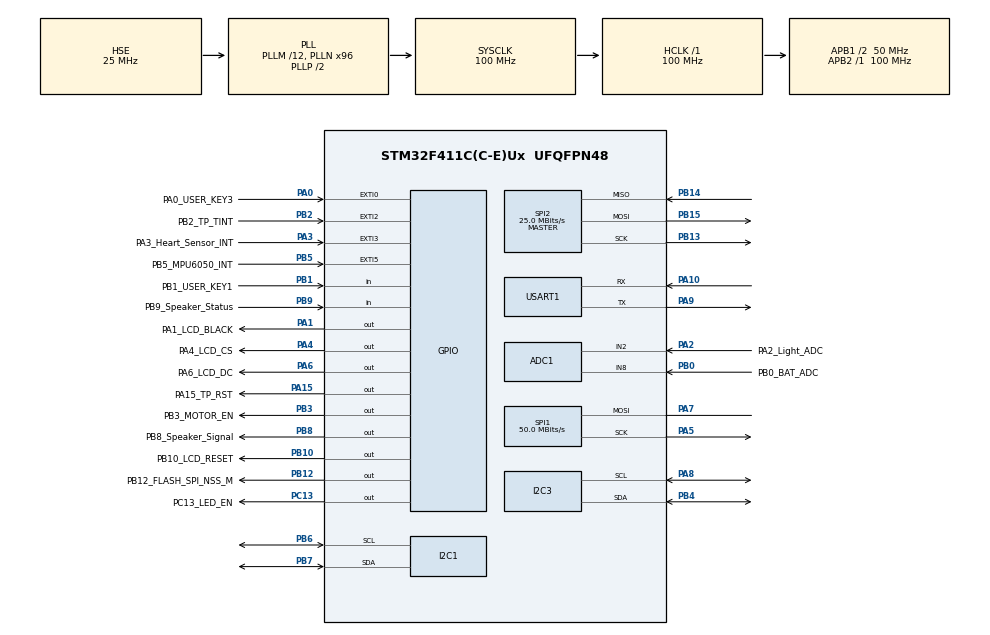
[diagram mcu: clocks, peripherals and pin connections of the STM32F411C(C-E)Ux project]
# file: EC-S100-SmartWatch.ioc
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ADC1.Channel-0\#ChannelRegularConversion=ADC_CHANNEL_8
ADC1.Channel-4\#ChannelRegularConversion=ADC_CHANNEL_VREFINT
ADC1.Channel-5\#ChannelRegularConversion=ADC_CHANNEL_8
ADC1.InjNumberOfConversion=0
ADC1.NbrOfConversion=3
ADC1.NbrOfConversionFlag=1
ADC1.Rank-0\#ChannelRegularConversion=1
ADC1.Rank-4\#ChannelRegularConversion=2
ADC1.Rank-5\#ChannelRegularConversion=3
ADC1.SamplingTime-0\#ChannelRegularConversion=ADC_SAMPLETIME_480CYCLES
ADC1.SamplingTime-4\#ChannelRegularConversion=ADC_SAMPLETIME_480CYCLES
ADC1.SamplingTime-5\#ChannelRegularConversion=ADC_SAMPLETIME_480CYCLES
ADC1.master=1
Dma.I2C1_RX.1.Direction=DMA_PERIPH_TO_MEMORY
Dma.I2C1_RX.1.FIFOMode=DMA_FIFOMODE_DISABLE
Dma.I2C1_RX.1.Instance=DMA1_Stream5
Dma.I2C1_RX.1.MemDataAlignment=DMA_MDATAALIGN_BYTE
Dma.I2C1_RX.1.MemInc=DMA_MINC_ENABLE
Dma.I2C1_RX.1.Mode=DMA_NORMAL
Dma.I2C1_RX.1.PeriphDataAlignment=DMA_PDATAALIGN_BYTE
Dma.I2C1_RX.1.PeriphInc=DMA_PINC_DISABLE
Dma.I2C1_RX.1.Priority=DMA_PRIORITY_LOW
Dma.I2C3_RX.2.Direction=DMA_PERIPH_TO_MEMORY
Dma.I2C3_RX.2.FIFOMode=DMA_FIFOMODE_DISABLE
Dma.I2C3_RX.2.Instance=DMA1_Stream1
Dma.I2C3_RX.2.MemDataAlignment=DMA_MDATAALIGN_BYTE
Dma.I2C3_RX.2.MemInc=DMA_MINC_ENABLE
Dma.I2C3_RX.2.Mode=DMA_NORMAL
Dma.I2C3_RX.2.PeriphDataAlignment=DMA_PDATAALIGN_BYTE
Dma.I2C3_RX.2.PeriphInc=DMA_PINC_DISABLE
Dma.I2C3_RX.2.Priority=DMA_PRIORITY_LOW
Dma.Request0=SPI2_TX
Dma.Request1=I2C1_RX
Dma.Request2=I2C3_RX
Dma.Request3=USART1_RX
Dma.Request4=SPI1_TX
Dma.SPI1_TX.4.Direction=DMA_MEMORY_TO_PERIPH
Dma.SPI1_TX.4.FIFOMode=DMA_FIFOMODE_DISABLE
Dma.SPI1_TX.4.Instance=DMA2_Stream3
Dma.SPI1_TX.4.MemDataAlignment=DMA_MDATAALIGN_BYTE
Dma.SPI1_TX.4.MemInc=DMA_MINC_ENABLE
Dma.SPI1_TX.4.Mode=DMA_NORMAL
Dma.SPI1_TX.4.PeriphDataAlignment=DMA_PDATAALIGN_BYTE
Dma.SPI1_TX.4.PeriphInc=DMA_PINC_DISABLE
Dma.SPI1_TX.4.Priority=DMA_PRIORITY_LOW
Dma.SPI2_TX.0.Direction=DMA_MEMORY_TO_PERIPH
Dma.SPI2_TX.0.FIFOMode=DMA_FIFOMODE_DISABLE
Dma.SPI2_TX.0.Instance=DMA1_Stream4
Dma.SPI2_TX.0.MemDataAlignment=DMA_MDATAALIGN_BYTE
Dma.SPI2_TX.0.MemInc=DMA_MINC_ENABLE
Dma.SPI2_TX.0.Mode=DMA_NORMAL
Dma.SPI2_TX.0.PeriphDataAlignment=DMA_PDATAALIGN_BYTE
Dma.SPI2_TX.0.PeriphInc=DMA_PINC_DISABLE
Dma.SPI2_TX.0.Priority=DMA_PRIORITY_VERY_HIGH
Dma.USART1_RX.3.Direction=DMA_PERIPH_TO_MEMORY
Dma.USART1_RX.3.FIFOMode=DMA_FIFOMODE_DISABLE
Dma.USART1_RX.3.Instance=DMA2_Stream2
Dma.USART1_RX.3.MemDataAlignment=DMA_MDATAALIGN_BYTE
Dma.USART1_RX.3.MemInc=DMA_MINC_ENABLE
Dma.USART1_RX.3.Mode=DMA_NORMAL
Dma.USART1_RX.3.PeriphDataAlignment=DMA_PDATAALIGN_BYTE
Dma.USART1_RX.3.PeriphInc=DMA_PINC_DISABLE
Dma.USART1_RX.3.Priority=DMA_PRIORITY_LOW
FREERTOS.Tasks01=defaultTask,24,256,StartDefaultTask,Default,NULL,Dynamic,NULL,NULL
Mcu.Family=STM32F4
Mcu.Name=STM32F411C(C-E)Ux
Mcu.Package=UFQFPN48
NVIC.DMA1_Stream1_IRQn=true\:5\:0\:false\:false\:true\:true\:false\:true\:true
NVIC.DMA1_Stream4_IRQn=true\:5\:0\:false\:false\:true\:true\:false\:true\:true
NVIC.DMA1_Stream5_IRQn=true\:5\:0\:false\:false\:true\:true\:false\:true\:true
NVIC.DMA2_Stream2_IRQn=true\:5\:0\:false\:false\:true\:true\:false\:true\:true
NVIC.DMA2_Stream3_IRQn=true\:5\:0\:false\:false\:true\:true\:false\:true\:true
NVIC.EXTI0_IRQn=true\:5\:0\:false\:false\:true\:true\:true\:true\:true
NVIC.EXTI2_IRQn=true\:5\:0\:false\:false\:true\:true\:true\:true\:true
NVIC.EXTI9_5_IRQn=true\:5\:0\:false\:false\:true\:true\:true\:true\:true
NVIC.PriorityGroup=NVIC_PRIORITYGROUP_4
NVIC.RTC_WKUP_IRQn=true\:5\:0\:false\:false\:true\:true\:true\:true\:true
NVIC.TIM1_TRG_COM_TIM11_IRQn=true\:15\:0\:false\:false\:true\:false\:false\:true\:true
NVIC.TimeBase=TIM1_TRG_COM_TIM11_IRQn
NVIC.TimeBaseIP=TIM11
NVIC.USART1_IRQn=true\:5\:0\:false\:false\:true\:true\:true\:true\:true
PA0-WKUP.GPIO_Label=PA0_USER_KEY3
PA0-WKUP.GPIO_ModeDefaultEXTI=GPIO_MODE_IT_FALLING
PA0-WKUP.Signal=GPXTI0
PA1.GPIO_Label=PA1_LCD_BLACK
PA1.PinState=GPIO_PIN_SET
PA1.Signal=GPIO_Output
PA10.Mode=Asynchronous
PA10.Signal=USART1_RX
PA13.Mode=Serial_Wire
PA13.Signal=SYS_JTMS-SWDIO
PA14.Mode=Serial_Wire
PA14.Signal=SYS_JTCK-SWCLK
PA15.GPIO_Label=PA15_TP_RST
PA15.PinState=GPIO_PIN_SET
PA15.Signal=GPIO_Output
PA2.GPIO_Label=PA2_Light_ADC
PA2.Signal=ADCx_IN2
PA3.GPIO_Label=PA3_Heart_Sensor_INT
PA3.GPIO_ModeDefaultEXTI=GPIO_MODE_IT_RISING_FALLING
PA3.Signal=GPXTI3
PA4.GPIO_Label=PA4_LCD_CS
PA4.PinState=GPIO_PIN_SET
PA4.Signal=GPIO_Output
PA5.Mode=Simplex_Bidirectional_Master
PA5.Signal=SPI1_SCK
PA6.GPIO_Label=PA6_LCD_DC
PA6.Signal=GPIO_Output
PA7.Mode=Simplex_Bidirectional_Master
PA7.Signal=SPI1_MOSI
PA8.Mode=I2C
PA8.Signal=I2C3_SCL
PA9.Mode=Asynchronous
PA9.Signal=USART1_TX
PB0.GPIO_Label=PB0_BAT_ADC
PB0.Signal=ADCx_IN8
PB1.GPIO_Label=PB1_USER_KEY1
PB1.GPIO_PuPd=GPIO_PULLUP
PB1.Signal=GPIO_Input
PB10.GPIO_Label=PB10_LCD_RESET
PB10.Signal=GPIO_Output
PB12.GPIO_Label=PB12_FLASH_SPI_NSS_M
PB12.Signal=GPIO_Output
PB13.Mode=Full_Duplex_Master
PB13.Signal=SPI2_SCK
PB14.Mode=Full_Duplex_Master
PB14.Signal=SPI2_MISO
PB15.Mode=Full_Duplex_Master
PB15.Signal=SPI2_MOSI
PB2.GPIO_Label=PB2_TP_TINT
PB2.GPIO_ModeDefaultEXTI=GPIO_MODE_IT_RISING
PB2.Signal=GPXTI2
PB3.GPIO_Label=PB3_MOTOR_EN
PB3.Signal=GPIO_Output
PB4.Mode=I2C
PB4.Signal=I2C3_SDA
PB5.GPIO_Label=PB5_MPU6050_INT
PB5.GPIO_ModeDefaultEXTI=GPIO_MODE_IT_FALLING
PB5.GPIO_PuPd=GPIO_PULLUP
PB5.Signal=GPXTI5
PB6.Mode=I2C
PB6.Signal=I2C1_SCL
PB7.Mode=I2C
PB7.Signal=I2C1_SDA
PB8.GPIO_Label=PB8_Speaker_Signal
PB8.Signal=GPIO_Output
PB9.GPIO_Label=PB9_Speaker_Status
PB9.Signal=GPIO_Input
PC13-ANTI_TAMP.GPIO_Label=PC13_LED_EN
PC13-ANTI_TAMP.Signal=GPIO_Output
PC14-OSC32_IN.Mode=LSE-External-Oscillator
PC14-OSC32_IN.Signal=RCC_OSC32_IN
PC15-OSC32_OUT.Mode=LSE-External-Oscillator
PC15-OSC32_OUT.Signal=RCC_OSC32_OUT
PH0\ -\ OSC_IN.Mode=HSE-External-Oscillator
PH0\ -\ OSC_IN.Signal=RCC_OSC_IN
PH1\ -\ OSC_OUT.Mode=HSE-External-Oscillator
PH1\ -\ OSC_OUT.Signal=RCC_OSC_OUT
ProjectManager.HeapSize=0x200
ProjectManager.StackSize=0x400
ProjectManager.TargetToolchain=MDK-ARM V5
RCC.48MHZClocksFreq_Value=50000000
RCC.AHBFreq_Value=100000000
RCC.APB1CLKDivider=RCC_HCLK_DIV2
RCC.APB1Freq_Value=50000000
RCC.APB1TimFreq_Value=100000000
RCC.APB2Freq_Value=100000000
RCC.APB2TimFreq_Value=100000000
RCC.CortexFreq_Value=100000000
RCC.HCLKFreq_Value=100000000
RCC.HSE_VALUE=25000000
RCC.HSI_VALUE=16000000
RCC.PLLM=12
RCC.PLLN=96
RCC.PLLSourceVirtual=RCC_PLLSOURCE_HSE
RCC.SYSCLKFreq_VALUE=100000000
RCC.SYSCLKSource=RCC_SYSCLKSOURCE_PLLCLK
RCC.VCOOutputFreq_Value=200000000
RTC.Date=2
RTC.Hours=12
RTC.WakeUpClock=RTC_WAKEUPCLOCK_CK_SPRE_16BITS
RTC.WakeUpCounter=3
RTC.WeekDay=RTC_WEEKDAY_FRIDAY
RTC.Year=26
SH.ADCx_IN2.0=ADC1_IN2,IN2
SH.ADCx_IN8.0=ADC1_IN8,IN8
SPI1.CLKPhase=SPI_PHASE_2EDGE
SPI1.CalculateBaudRate=50.0 MBits/s
SPI1.Direction=SPI_DIRECTION_1LINE
SPI1.Mode=SPI_MODE_MASTER
SPI1.VirtualType=VM_MASTER
SPI2.CalculateBaudRate=25.0 MBits/s
SPI2.Direction=SPI_DIRECTION_2LINES
SPI2.Mode=SPI_MODE_MASTER
SPI2.VirtualType=VM_MASTER
USART1.VirtualMode=VM_ASYNC
VP_ADC1_Vref_Input.Mode=IN-Vrefint
VP_FREERTOS_VS_CMSIS_V2.Mode=CMSIS_V2
VP_RTC_VS_RTC_Activate.Mode=RTC_Enabled
VP_RTC_VS_RTC_Calendar.Mode=RTC_Calendar
VP_RTC_VS_RTC_WakeUp_intern.Mode=WakeUp
VP_SYS_VS_tim11.Mode=TIM11
board=custom

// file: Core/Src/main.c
/* USER CODE BEGIN Header */
/**
  ******************************************************************************
  * @file           : main.c
  * @brief          : Main program body
  ******************************************************************************
  * @attention
  *
  * Copyright (c) 2026 STMicroelectronics.
  * All rights reserved.
  *
  * This software is licensed under terms that can be found in the LICENSE file
  * in the root directory of this software component.
  * If no LICENSE file comes with this software, it is provided AS-IS.
  *
  ******************************************************************************
  */
/* USER CODE END Header */
#include "main.h"
#include "cmsis_os.h"
#include "adc.h"
#include "dma.h"
#include "i2c.h"
#include "rtc.h"
#include "spi.h"
#include "usart.h"
#include "gpio.h"

void SystemClock_Config(void);
void MX_FREERTOS_Init(void);

int main(void)
{

  /* MCU Configuration--------------------------------------------------------*/

  /* Reset of all peripherals, Initializes the Flash interface and the Systick. */
  HAL_Init();

  /* Configure the system clock */
  SystemClock_Config();

  /* Initialize all configured peripherals */
  MX_GPIO_Init();
  MX_DMA_Init();
  MX_ADC1_Init();
  MX_I2C1_Init();
  MX_I2C3_Init();
  MX_SPI1_Init();
  MX_SPI2_Init();
  MX_USART1_UART_Init();
  MX_RTC_Init();

  /* Init scheduler */
  osKernelInitialize();  /* Call init function for freertos objects (in freertos.c) */
  MX_FREERTOS_Init();

  /* Start scheduler */
  osKernelStart();
  /* We should never get here as control is now taken by the scheduler */
  /* Infinite loop */
  while (1)
  {

  }
}

void SystemClock_Config(void)
{
  RCC_OscInitTypeDef RCC_OscInitStruct = {0};
  RCC_ClkInitTypeDef RCC_ClkInitStruct = {0};

  /** Configure the main internal regulator output voltage
  */
  __HAL_RCC_PWR_CLK_ENABLE();
  __HAL_PWR_VOLTAGESCALING_CONFIG(PWR_REGULATOR_VOLTAGE_SCALE1);

  /** Initializes the RCC Oscillators according to the specified parameters
  * in the RCC_OscInitTypeDef structure.
  */
  RCC_OscInitStruct.OscillatorType = RCC_OSCILLATORTYPE_LSI|RCC_OSCILLATORTYPE_HSE;
  RCC_OscInitStruct.HSEState = RCC_HSE_ON;
  RCC_OscInitStruct.LSIState = RCC_LSI_ON;
  RCC_OscInitStruct.PLL.PLLState = RCC_PLL_ON;
  RCC_OscInitStruct.PLL.PLLSource = RCC_PLLSOURCE_HSE;
  RCC_OscInitStruct.PLL.PLLM = 12;
  RCC_OscInitStruct.PLL.PLLN = 96;
  RCC_OscInitStruct.PLL.PLLP = RCC_PLLP_DIV2;
  RCC_OscInitStruct.PLL.PLLQ = 4;
  if (HAL_RCC_OscConfig(&RCC_OscInitStruct) != HAL_OK)
  {
    Error_Handler();
  }

  /** Initializes the CPU, AHB and APB buses clocks
  */
  RCC_ClkInitStruct.ClockType = RCC_CLOCKTYPE_HCLK|RCC_CLOCKTYPE_SYSCLK
                              |RCC_CLOCKTYPE_PCLK1|RCC_CLOCKTYPE_PCLK2;
  RCC_ClkInitStruct.SYSCLKSource = RCC_SYSCLKSOURCE_PLLCLK;
  RCC_ClkInitStruct.AHBCLKDivider = RCC_SYSCLK_DIV1;
  RCC_ClkInitStruct.APB1CLKDivider = RCC_HCLK_DIV2;
  RCC_ClkInitStruct.APB2CLKDivider = RCC_HCLK_DIV1;

  if (HAL_RCC_ClockConfig(&RCC_ClkInitStruct, FLASH_LATENCY_3) != HAL_OK)
  {
    Error_Handler();
  }
}

void HAL_TIM_PeriodElapsedCallback(TIM_HandleTypeDef *htim)
{
  if (htim->Instance == TIM11) {
    HAL_IncTick();
  }
}

void Error_Handler(void)
{
  __disable_irq();
  while (1)
  {
  }
}

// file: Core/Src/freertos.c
/* USER CODE BEGIN Header */
/**
  ******************************************************************************
  * File Name          : freertos.c
  * Description        : Code for freertos applications
  ******************************************************************************
  * @attention
  *
  * Copyright (c) 2026 STMicroelectronics.
  * All rights reserved.
  *
  * This software is licensed under terms that can be found in the LICENSE file
  * in the root directory of this software component.
  * If no LICENSE file comes with this software, it is provided AS-IS.
  *
  ******************************************************************************
  */
/* USER CODE END Header */

#include "FreeRTOS.h"
#include "task.h"
#include "main.h"
#include "cmsis_os.h"

/* USER CODE BEGIN Includes */
#include "app_boot.h"
#include "app_system.h"

/* USER CODE END Includes */

/* Definitions for defaultTask */
osThreadId_t defaultTaskHandle;
const osThreadAttr_t defaultTask_attributes = {
  .name = "defaultTask",
  .stack_size = 256 * 4,
  .priority = (osPriority_t) osPriorityNormal,
};

void StartDefaultTask(void *argument);

void MX_FREERTOS_Init(void); /* (MISRA C 2004 rule 8.1) */

void MX_FREERTOS_Init(void) {

  /* Create the thread(s) */
  /* creation of defaultTask */
  defaultTaskHandle = osThreadNew(StartDefaultTask, NULL, &defaultTask_attributes);

}

void StartDefaultTask(void *argument)
{
  /* USER CODE BEGIN StartDefaultTask */
  platform_err_t ret = PLATFORM_ERR_OK;

  (void)argument;

  ret = app_boot_init();
  if (PLATFORM_ERR_OK != ret)
  {
    app_system_record_error(ret);
  }

  /* Infinite loop */
  for(;;)
  {
    ret = app_system_process();
    if (PLATFORM_ERR_OK != ret)
    {
      app_system_record_error(ret);
    }

    osDelay(10);
  }
  /* USER CODE END StartDefaultTask */
}
